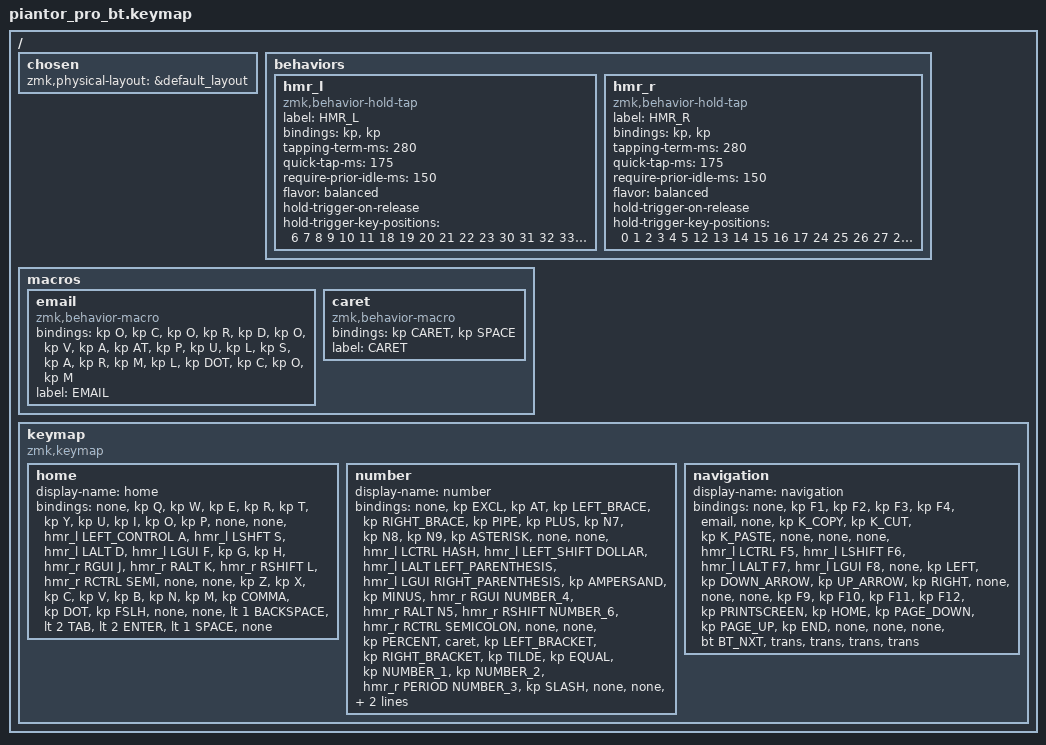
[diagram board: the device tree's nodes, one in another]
/*
 * Copyright (c) 2020 The ZMK Contributors
 *
 * SPDX-License-Identifier: MIT
 */

#include <behaviors.dtsi>
#include <dt-bindings/zmk/bt.h>
#include <dt-bindings/zmk/keys.h>

/ {
    chosen { zmk,physical-layout = &default_layout; };
};

/ {
    behaviors {
        hmr_l: hmr_l {
            compatible = "zmk,behavior-hold-tap";
            label = "HMR_L";
            bindings = <&kp>, <&kp>;

            #binding-cells = <2>;
            tapping-term-ms = <280>;
            quick-tap-ms = <175>;
            require-prior-idle-ms = <150>;
            flavor = "balanced";
            hold-trigger-on-release;
            hold-trigger-key-positions = <6 7 8 9 10 11 18 19 20 21 22 23 30 31 32 33 34 35 40 41 39>;
        };

        hmr_r: hmr_r {
            compatible = "zmk,behavior-hold-tap";
            label = "HMR_R";
            bindings = <&kp>, <&kp>;

            #binding-cells = <2>;
            tapping-term-ms = <280>;
            quick-tap-ms = <175>;
            require-prior-idle-ms = <150>;
            flavor = "balanced";
            hold-trigger-on-release;
            hold-trigger-key-positions = <0 1 2 3 4 5 12 13 14 15 16 17 24 25 26 27 28 29 36 37 38>;
        };
    };

    macros {
        email: email {
            compatible = "zmk,behavior-macro";
            #binding-cells = <0>;
            bindings = <&kp O &kp C &kp O &kp R &kp D &kp O &kp V &kp A &kp AT &kp P &kp U &kp L &kp S &kp A &kp R &kp M &kp L &kp DOT &kp C &kp O &kp M>;
            label = "EMAIL";
        };

        caret: caret {
            compatible = "zmk,behavior-macro";
            #binding-cells = <0>;
            bindings = <&kp CARET &kp SPACE>;
            label = "CARET";
        };
    };

    keymap {
        compatible = "zmk,keymap";

        home {
            display-name = "home";

            // --------------------------------------------------------------------------------
            // |  TAB |  Q  |  W  |  E  |  R  |  T  |  Y  |  U   |  I  |  O  |  P  | BSPC |
            // | CTRL |  A  |  S  |  D  |  F  |  G  |  H  |  J   |  K  |  L  |  ;  |  '   |
            // | SHFT |  Z  |  X  |  C  |  V  |  B  |  N  |  M   |  ,  |  .  |  /  | ESC  |
            //                    | GUI | LWR | SPC | ENT | RSE  | ALT |

            bindings = <
&none  &kp Q  &kp W  &kp E  &kp R  &kp T  &kp Y  &kp U  &kp I  &kp O  &kp P  &none  &none  &hmr_l LEFT_CONTROL A  &hmr_l LSHFT S  &hmr_l LALT D  &hmr_l LGUI F  &kp G  &kp H  &hmr_r RGUI J  &hmr_r RALT K  &hmr_r RSHIFT L  &hmr_r RCTRL SEMI  &none  &none  &kp Z  &kp X  &kp C  &kp V  &kp B  &kp N  &kp M  &kp COMMA  &kp DOT  &kp FSLH  &none  &none  &lt 1 BACKSPACE  &lt 2 TAB  &lt 2 ENTER  &lt 1 SPACE  &none
            >;
        };

        number {
            display-name = "number";

            // -----------------------------------------------------------------------------------------
            // |  TAB |  1  |  2  |  3  |  4  |  5    |  6  |  7  |  8  |  9  |  0  | BSPC |
            // | CTRL | BT1 | BT2 | BT3 | BT4 | BT5   | LFT | DWN |  UP | RGT |     |      |
            // | SHFT | BTCR| RGB | RST | BOOT| Unlock|     |     |     |     |     |      |
            //                    | GUI |     | SPC   | ENT |     | ALT |

            bindings = <
&none  &kp EXCL  &kp AT  &kp LEFT_BRACE  &kp RIGHT_BRACE  &kp PIPE  &kp PLUS  &kp N7  &kp N8  &kp N9  &kp ASTERISK  &none  &none  &hmr_l LCTRL HASH  &hmr_l LEFT_SHIFT DOLLAR  &hmr_l LALT LEFT_PARENTHESIS  &hmr_l LGUI RIGHT_PARENTHESIS  &kp AMPERSAND  &kp MINUS  &hmr_r RGUI NUMBER_4  &hmr_r RALT N5  &hmr_r RSHIFT NUMBER_6  &hmr_r RCTRL SEMICOLON  &none  &none  &kp PERCENT  &caret  &kp LEFT_BRACKET  &kp RIGHT_BRACKET  &kp TILDE  &kp EQUAL  &kp NUMBER_1  &kp NUMBER_2  &hmr_r PERIOD NUMBER_3  &kp SLASH  &none  &none  &kp BACKSLASH  &kp GRAVE  &kp SPACE  &kp N0  &none
            >;
        };

        navigation {
            display-name = "navigation";

            // -----------------------------------------------------------------------------------------
            // |  TAB |  !  |  @  |  #  |  $  |  %  |  ^  |  &  |  *  |  (  |  )  | BSPC |
            // | CTRL |     |     |     |     |     |  -  |  =  |  [  |  ]  |  \  |  `   |
            // | SHFT |     |     |     |     |     |  _  |  +  |  {  |  }  | "|" |  ~   |
            //                    | GUI |     | SPC | ENT |     | ALT |

            bindings = <
&none  &kp F1  &kp F2  &kp F3  &kp F4  &email  &none  &kp K_COPY  &kp K_CUT  &kp K_PASTE  &none  &none  &none  &hmr_l LCTRL F5  &hmr_l LSHIFT F6  &hmr_l LALT F7  &hmr_l LGUI F8  &none  &kp LEFT  &kp DOWN_ARROW  &kp UP_ARROW  &kp RIGHT  &none  &none  &none  &kp F9  &kp F10  &kp F11  &kp F12  &kp PRINTSCREEN  &kp HOME  &kp PAGE_DOWN  &kp PAGE_UP  &kp END  &none  &none  &none  &bt BT_NXT  &trans  &trans  &trans  &trans
            >;
        };
    };
};
